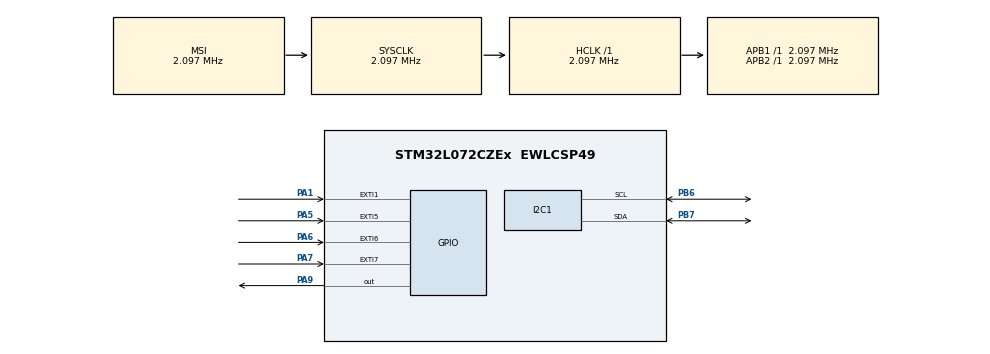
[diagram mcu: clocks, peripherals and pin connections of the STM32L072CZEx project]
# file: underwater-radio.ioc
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Mcu.Family=STM32L0
RCC.MSI_VALUE=2097000
ProjectManager.StackSize=0x400
RCC.HSI16_VALUE=16000000
ProjectManager.TargetToolchain=STM32CubeIDE
RCC.APB2TimFreq_Value=2097000
PA9.Signal=GPIO_Output
PB6.Signal=I2C1_SCL
PB6.Mode=I2C
RCC.LSE_VALUE=32768
PA1.GPIO_PuPd=GPIO_PULLUP
PA1.Signal=GPXTI1
PA7.GPIO_PuPd=GPIO_PULLUP
RCC.AHBFreq_Value=2097000
PA5.Signal=GPXTI5
RCC.HSE_VALUE=8000000
board=custom
RCC.VCOOutputFreq_Value=48000000
RCC.APB2Freq_Value=2097000
PA6.GPIO_PuPd=GPIO_PULLUP
PA5.GPIO_PuPd=GPIO_PULLUP
PB7.Signal=I2C1_SDA
Mcu.Name=STM32L072CZEx
RCC.SYSCLKFreq_VALUE=2097000
Mcu.Package=EWLCSP49
PA6.Signal=GPXTI6
PB7.Mode=I2C
ProjectManager.HeapSize=0x200
RCC.HSI_VALUE=16000000
RCC.APB1TimFreq_Value=2097000
RCC.APB1Freq_Value=2097000
NVIC.EXTI4_15_IRQn=true\:0\:0\:false\:false\:true\:true\:true
RCC.HSI48_VALUE=48000000
PA7.Signal=GPXTI7
NVIC.EXTI0_1_IRQn=true\:0\:0\:false\:false\:true\:true\:true

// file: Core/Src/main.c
/* USER CODE BEGIN Header */
/**
  ******************************************************************************
  * @file           : main.c
  * @brief          : Main program body
  ******************************************************************************
  * @attention
  *
  * <h2><center>&copy; Copyright (c) 2021 STMicroelectronics.
  * All rights reserved.</center></h2>
  *
  * This software component is licensed by ST under BSD 3-Clause license,
  * the "License"; You may not use this file except in compliance with the
  * License. You may obtain a copy of the License at:
  *                        opensource.org/licenses/BSD-3-Clause
  *
  ******************************************************************************
  */
/* USER CODE END Header */
#include "main.h"
#include "stdio.h"

I2C_HandleTypeDef hi2c1;

void SystemClock_Config(void);
static void MX_GPIO_Init(void);
static void MX_I2C1_Init(void);

int main(void)
{

  /* MCU Configuration--------------------------------------------------------*/

  /* Reset of all peripherals, Initializes the Flash interface and the Systick. */
  HAL_Init();

  /* Configure the system clock */
  SystemClock_Config();

  /* Initialize all configured peripherals */
  MX_GPIO_Init();
  MX_I2C1_Init();

  /* Infinite loop */
  while (1)
  {

    /* USER CODE BEGIN 3 */
//	HAL_GPIO_WritePin(GPIOA, GPIO_PIN_9, GPIO_PIN_RESET);
//	HAL_Delay(2000);
//	HAL_GPIO_WritePin(GPIOA, GPIO_PIN_9, GPIO_PIN_SET);
//	HAL_Delay(2000);

	unsigned int i, ret;
	for(i=1; i<128; i++)
	{

		ret = HAL_I2C_IsDeviceReady(&hi2c1, (uint16_t)(i<<1), 3, 5);
	   	if (ret != HAL_OK) /* No ACK Received At That Address */
	   	{
	   		printf("I2C device not found");
	    }
	   	else if(ret == HAL_OK)
	   	{
	   		printf("I2C device found");
	   	}
	}
  }
  /* USER CODE END 3 */
}

void SystemClock_Config(void)
{
  RCC_OscInitTypeDef RCC_OscInitStruct = {0};
  RCC_ClkInitTypeDef RCC_ClkInitStruct = {0};
  RCC_PeriphCLKInitTypeDef PeriphClkInit = {0};

  /** Configure the main internal regulator output voltage
  */
  __HAL_PWR_VOLTAGESCALING_CONFIG(PWR_REGULATOR_VOLTAGE_SCALE1);
  /** Initializes the RCC Oscillators according to the specified parameters
  * in the RCC_OscInitTypeDef structure.
  */
  RCC_OscInitStruct.OscillatorType = RCC_OSCILLATORTYPE_MSI;
  RCC_OscInitStruct.MSIState = RCC_MSI_ON;
  RCC_OscInitStruct.MSICalibrationValue = 0;
  RCC_OscInitStruct.MSIClockRange = RCC_MSIRANGE_5;
  RCC_OscInitStruct.PLL.PLLState = RCC_PLL_NONE;
  if (HAL_RCC_OscConfig(&RCC_OscInitStruct) != HAL_OK)
  {
    Error_Handler();
  }
  /** Initializes the CPU, AHB and APB buses clocks
  */
  RCC_ClkInitStruct.ClockType = RCC_CLOCKTYPE_HCLK|RCC_CLOCKTYPE_SYSCLK
                              |RCC_CLOCKTYPE_PCLK1|RCC_CLOCKTYPE_PCLK2;
  RCC_ClkInitStruct.SYSCLKSource = RCC_SYSCLKSOURCE_MSI;
  RCC_ClkInitStruct.AHBCLKDivider = RCC_SYSCLK_DIV1;
  RCC_ClkInitStruct.APB1CLKDivider = RCC_HCLK_DIV1;
  RCC_ClkInitStruct.APB2CLKDivider = RCC_HCLK_DIV1;

//  if (HAL_RCC_ClockConfig(&RCC_ClkInitStruct, FLASH_LATENCY_0) != HAL_OK)
//  {
//    Error_Handler();
//  }
//  PeriphClkInit.PeriphClockSelection = RCC_PERIPHCLK_I2C1;
//  PeriphClkInit.I2c1ClockSelection = RCC_I2C1CLKSOURCE_PCLK1;
//  if (HAL_RCCEx_PeriphCLKConfig(&PeriphClkInit) != HAL_OK)
//  {
//    Error_Handler();
//  }
}

static void MX_I2C1_Init(void)
{

  hi2c1.Instance = I2C1;
  hi2c1.Init.Timing = 0x00000708;
  hi2c1.Init.OwnAddress1 = 0;
  hi2c1.Init.AddressingMode = I2C_ADDRESSINGMODE_7BIT;
  hi2c1.Init.DualAddressMode = I2C_DUALADDRESS_DISABLE;
  hi2c1.Init.OwnAddress2 = 0;
  hi2c1.Init.OwnAddress2Masks = I2C_OA2_NOMASK;
  hi2c1.Init.GeneralCallMode = I2C_GENERALCALL_DISABLE;
  hi2c1.Init.NoStretchMode = I2C_NOSTRETCH_DISABLE;
  if (HAL_I2C_Init(&hi2c1) != HAL_OK)
  {
    Error_Handler();
  }
//  /** Configure Analogue filter
//  */
//  if (HAL_I2CEx_ConfigAnalogFilter(&hi2c1, I2C_ANALOGFILTER_ENABLE) != HAL_OK)
//  {
//    Error_Handler();
//  }
//  /** Configure Digital filter
//  */
//  if (HAL_I2CEx_ConfigDigitalFilter(&hi2c1, 0) != HAL_OK)
//  {
//    Error_Handler();
//  }

}

static void MX_GPIO_Init(void)
{
  GPIO_InitTypeDef GPIO_InitStruct = {0};

  /* GPIO Ports Clock Enable */
  __HAL_RCC_GPIOB_CLK_ENABLE();
  __HAL_RCC_GPIOA_CLK_ENABLE();

  /*Configure GPIO pin Output Level */
  HAL_GPIO_WritePin(GPIOA, GPIO_PIN_9, GPIO_PIN_RESET);

  /*Configure GPIO pin : PA9 */
  GPIO_InitStruct.Pin = GPIO_PIN_9;
  GPIO_InitStruct.Mode = GPIO_MODE_OUTPUT_PP;
  GPIO_InitStruct.Pull = GPIO_NOPULL;
  GPIO_InitStruct.Speed = GPIO_SPEED_FREQ_LOW;
  HAL_GPIO_Init(GPIOA, &GPIO_InitStruct);

  /*Configure GPIO pins : PA1 PA7 PA6 PA5 */
  GPIO_InitStruct.Pin = GPIO_PIN_1|GPIO_PIN_7|GPIO_PIN_6|GPIO_PIN_5;
  GPIO_InitStruct.Mode = GPIO_MODE_IT_RISING;
  GPIO_InitStruct.Pull = GPIO_PULLUP;
  HAL_GPIO_Init(GPIOA, &GPIO_InitStruct);

  /* EXTI interrupt init*/
  HAL_NVIC_SetPriority(EXTI0_1_IRQn, 0, 0);
  HAL_NVIC_EnableIRQ(EXTI0_1_IRQn);

  HAL_NVIC_SetPriority(EXTI4_15_IRQn, 0, 0);
  HAL_NVIC_EnableIRQ(EXTI4_15_IRQn);

}

void Error_Handler(void)
{
}

/************************ (C) COPYRIGHT STMicroelectronics *****END OF FILE****/
